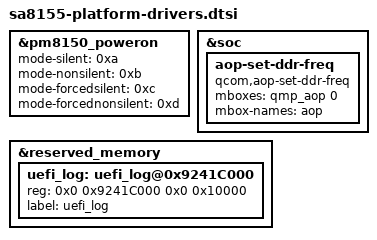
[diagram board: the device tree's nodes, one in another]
&pm8150_poweron {
	mode-silent = <0xa>;
	mode-nonsilent = <0xb>;
	mode-forcedsilent = <0xc>;
	mode-forcednonsilent = <0xd>;
};

&soc {
	aop-set-ddr-freq {
		compatible = "qcom,aop-set-ddr-freq";
		mboxes = <&qmp_aop 0>;
		mbox-names = "aop";
	};
};

&reserved_memory {
	uefi_log: uefi_log@0x9241C000 {
		reg = <0x0 0x9241C000 0x0 0x10000>;
		label = "uefi_log";
	};
};
